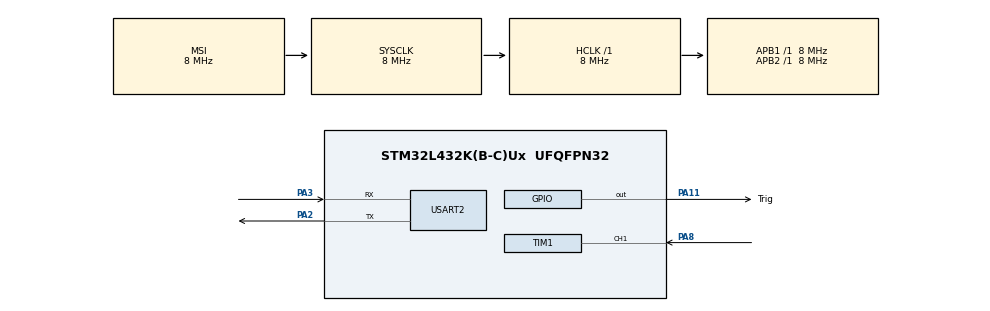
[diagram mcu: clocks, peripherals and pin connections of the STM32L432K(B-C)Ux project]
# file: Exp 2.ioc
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Mcu.Family=STM32L4
Mcu.Name=STM32L432K(B-C)Ux
Mcu.Package=UFQFPN32
NVIC.PriorityGroup=NVIC_PRIORITYGROUP_4
NVIC.TIM1_CC_IRQn=true\:0\:0\:false\:false\:true\:true\:true
PA11.GPIO_Label=Trig
PA11.Signal=GPIO_Output
PA13\ (JTMS-SWDIO).Mode=Serial_Wire
PA13\ (JTMS-SWDIO).Signal=SYS_JTMS-SWDIO
PA14\ (JTCK-SWCLK).Mode=Serial_Wire
PA14\ (JTCK-SWCLK).Signal=SYS_JTCK-SWCLK
PA2.Mode=Asynchronous
PA2.Signal=USART2_TX
PA3.Mode=Asynchronous
PA3.Signal=USART2_RX
PA8.Signal=S_TIM1_CH1
PC14-OSC32_IN\ (PC14).Mode=LSE-External-Oscillator
PC14-OSC32_IN\ (PC14).Signal=RCC_OSC32_IN
PC15-OSC32_OUT\ (PC15).Mode=LSE-External-Oscillator
PC15-OSC32_OUT\ (PC15).Signal=RCC_OSC32_OUT
ProjectManager.HeapSize=0x200
ProjectManager.StackSize=0x400
ProjectManager.TargetToolchain=MDK-ARM V5
RCC.ADCFreq_Value=16000000
RCC.AHBFreq_Value=8000000
RCC.APB1Freq_Value=8000000
RCC.APB1TimFreq_Value=8000000
RCC.APB2Freq_Value=8000000
RCC.APB2TimFreq_Value=8000000
RCC.CortexFreq_Value=8000000
RCC.HCLKFreq_Value=8000000
RCC.HSE_VALUE=8000000
RCC.HSI48_VALUE=48000000
RCC.HSI_VALUE=16000000
RCC.MSIClockRange=RCC_MSIRANGE_7
RCC.MSI_VALUE=8000000
RCC.PLLM=2
RCC.SYSCLKFreq_VALUE=8000000
RCC.USBFreq_Value=16000000
RCC.VCOOutputFreq_Value=32000000
SH.S_TIM1_CH1.0=TIM1_CH1,Input_Capture1_from_TI1
TIM1.Channel-Input_Capture1_from_TI1=TIM_CHANNEL_1
TIM1.Prescaler=7
USART2.VirtualMode-Asynchronous=VM_ASYNC
board=custom

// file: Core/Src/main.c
/* USER CODE BEGIN Header */
/**
  ******************************************************************************
  * @file           : main.c
  * @brief          : Main program body
  ******************************************************************************
  * @attention
  *
  * <h2><center>&copy; Copyright (c) 2021 STMicroelectronics.
  * All rights reserved.</center></h2>
  *
  * This software component is licensed by ST under BSD 3-Clause license,
  * the "License"; You may not use this file except in compliance with the
  * License. You may obtain a copy of the License at:
  *                        opensource.org/licenses/BSD-3-Clause
  *
  ******************************************************************************
  */
/* USER CODE END Header */
#include "main.h"

TIM_HandleTypeDef htim1;

UART_HandleTypeDef huart2;

void SystemClock_Config(void);
static void MX_GPIO_Init(void);
static void MX_TIM1_Init(void);
static void MX_USART2_UART_Init(void);
void delay (uint16_t time);

/* USER CODE BEGIN 0 */
extern uint8_t Distance;
/* USER CODE END 0 */

int main(void)
{

  /* MCU Configuration--------------------------------------------------------*/

  /* Reset of all peripherals, Initializes the Flash interface and the Systick. */
  HAL_Init();

  /* Configure the system clock */
  SystemClock_Config();

  /* Initialize all configured peripherals */
  MX_GPIO_Init();
  MX_TIM1_Init();
  MX_USART2_UART_Init();
	HAL_TIM_Base_Start(&htim1);
  /* USER CODE BEGIN 2 */
HAL_GPIO_WritePin (GPIOA, GPIO_PIN_11,GPIO_PIN_RESET);
HAL_Delay(10);
  /* USER CODE END 2 */

  /* Infinite loop */
  while (1)
  {
		HAL_GPIO_WritePin (GPIOA, GPIO_PIN_11,GPIO_PIN_SET);    //PULL the Trig pin high
		delay(10); //wait for 10 MicroSec
		HAL_GPIO_WritePin (GPIOA, GPIO_PIN_11,GPIO_PIN_RESET);  //Pull the Trig pin Low
		HAL_TIM_IC_Start_IT(&htim1, TIM_CHANNEL_1);
		HAL_Delay(100);
  }
}

void SystemClock_Config(void)
{
  RCC_OscInitTypeDef RCC_OscInitStruct = {0};
  RCC_ClkInitTypeDef RCC_ClkInitStruct = {0};
  RCC_PeriphCLKInitTypeDef PeriphClkInit = {0};

  /** Configure LSE Drive Capability
  */
  HAL_PWR_EnableBkUpAccess();
  __HAL_RCC_LSEDRIVE_CONFIG(RCC_LSEDRIVE_LOW);
  /** Initializes the RCC Oscillators according to the specified parameters
  * in the RCC_OscInitTypeDef structure.
  */
  RCC_OscInitStruct.OscillatorType = RCC_OSCILLATORTYPE_LSE|RCC_OSCILLATORTYPE_MSI;
  RCC_OscInitStruct.LSEState = RCC_LSE_ON;
  RCC_OscInitStruct.MSIState = RCC_MSI_ON;
  RCC_OscInitStruct.MSICalibrationValue = 0;
  RCC_OscInitStruct.MSIClockRange = RCC_MSIRANGE_7;
  RCC_OscInitStruct.PLL.PLLState = RCC_PLL_NONE;
  if (HAL_RCC_OscConfig(&RCC_OscInitStruct) != HAL_OK)
  {
    Error_Handler();
  }
  /** Initializes the CPU, AHB and APB buses clocks
  */
  RCC_ClkInitStruct.ClockType = RCC_CLOCKTYPE_HCLK|RCC_CLOCKTYPE_SYSCLK
                              |RCC_CLOCKTYPE_PCLK1|RCC_CLOCKTYPE_PCLK2;
  RCC_ClkInitStruct.SYSCLKSource = RCC_SYSCLKSOURCE_MSI;
  RCC_ClkInitStruct.AHBCLKDivider = RCC_SYSCLK_DIV1;
  RCC_ClkInitStruct.APB1CLKDivider = RCC_HCLK_DIV1;
  RCC_ClkInitStruct.APB2CLKDivider = RCC_HCLK_DIV1;

  if (HAL_RCC_ClockConfig(&RCC_ClkInitStruct, FLASH_LATENCY_0) != HAL_OK)
  {
    Error_Handler();
  }
  PeriphClkInit.PeriphClockSelection = RCC_PERIPHCLK_USART2;
  PeriphClkInit.Usart2ClockSelection = RCC_USART2CLKSOURCE_PCLK1;
  if (HAL_RCCEx_PeriphCLKConfig(&PeriphClkInit) != HAL_OK)
  {
    Error_Handler();
  }
  /** Configure the main internal regulator output voltage
  */
  if (HAL_PWREx_ControlVoltageScaling(PWR_REGULATOR_VOLTAGE_SCALE1) != HAL_OK)
  {
    Error_Handler();
  }
  /** Enable MSI Auto calibration
  */
  HAL_RCCEx_EnableMSIPLLMode();
}

static void MX_TIM1_Init(void)
{

  TIM_MasterConfigTypeDef sMasterConfig = {0};
  TIM_IC_InitTypeDef sConfigIC = {0};

  htim1.Instance = TIM1;
  htim1.Init.Prescaler = 7;
  htim1.Init.CounterMode = TIM_COUNTERMODE_UP;
  htim1.Init.Period = 65535;
  htim1.Init.ClockDivision = TIM_CLOCKDIVISION_DIV1;
  htim1.Init.RepetitionCounter = 0;
  htim1.Init.AutoReloadPreload = TIM_AUTORELOAD_PRELOAD_DISABLE;
  if (HAL_TIM_IC_Init(&htim1) != HAL_OK)
  {
    Error_Handler();
  }
  sMasterConfig.MasterOutputTrigger = TIM_TRGO_RESET;
  sMasterConfig.MasterOutputTrigger2 = TIM_TRGO2_RESET;
  sMasterConfig.MasterSlaveMode = TIM_MASTERSLAVEMODE_DISABLE;
  if (HAL_TIMEx_MasterConfigSynchronization(&htim1, &sMasterConfig) != HAL_OK)
  {
    Error_Handler();
  }
  sConfigIC.ICPolarity = TIM_INPUTCHANNELPOLARITY_RISING;
  sConfigIC.ICSelection = TIM_ICSELECTION_DIRECTTI;
  sConfigIC.ICPrescaler = TIM_ICPSC_DIV1;
  sConfigIC.ICFilter = 0;
  if (HAL_TIM_IC_ConfigChannel(&htim1, &sConfigIC, TIM_CHANNEL_1) != HAL_OK)
  {
    Error_Handler();
  }

}

static void MX_USART2_UART_Init(void)
{

  huart2.Instance = USART2;
  huart2.Init.BaudRate = 115200;
  huart2.Init.WordLength = UART_WORDLENGTH_8B;
  huart2.Init.StopBits = UART_STOPBITS_1;
  huart2.Init.Parity = UART_PARITY_NONE;
  huart2.Init.Mode = UART_MODE_TX_RX;
  huart2.Init.HwFlowCtl = UART_HWCONTROL_NONE;
  huart2.Init.OverSampling = UART_OVERSAMPLING_16;
  huart2.Init.OneBitSampling = UART_ONE_BIT_SAMPLE_DISABLE;
  huart2.AdvancedInit.AdvFeatureInit = UART_ADVFEATURE_NO_INIT;
  if (HAL_UART_Init(&huart2) != HAL_OK)
  {
    Error_Handler();
  }

}

static void MX_GPIO_Init(void)
{
  GPIO_InitTypeDef GPIO_InitStruct = {0};

  /* GPIO Ports Clock Enable */
  __HAL_RCC_GPIOC_CLK_ENABLE();
  __HAL_RCC_GPIOA_CLK_ENABLE();

  /*Configure GPIO pin Output Level */
  HAL_GPIO_WritePin(Trig_GPIO_Port, Trig_Pin, GPIO_PIN_RESET);

  /*Configure GPIO pin : Trig_Pin */
  GPIO_InitStruct.Pin = Trig_Pin;
  GPIO_InitStruct.Mode = GPIO_MODE_OUTPUT_PP;
  GPIO_InitStruct.Pull = GPIO_NOPULL;
  GPIO_InitStruct.Speed = GPIO_SPEED_FREQ_LOW;
  HAL_GPIO_Init(Trig_GPIO_Port, &GPIO_InitStruct);

}

/* USER CODE BEGIN 4 */
void delay (uint16_t time)
{
	__HAL_TIM_SetCounter(&htim1,0);
	while (__HAL_TIM_GetCounter (&htim1) < time);
}

/* USER CODE END 4 */

void Error_Handler(void)
{
  __disable_irq();
  while (1)
  {
  }
}

/************************ (C) COPYRIGHT STMicroelectronics *****END OF FILE****/
